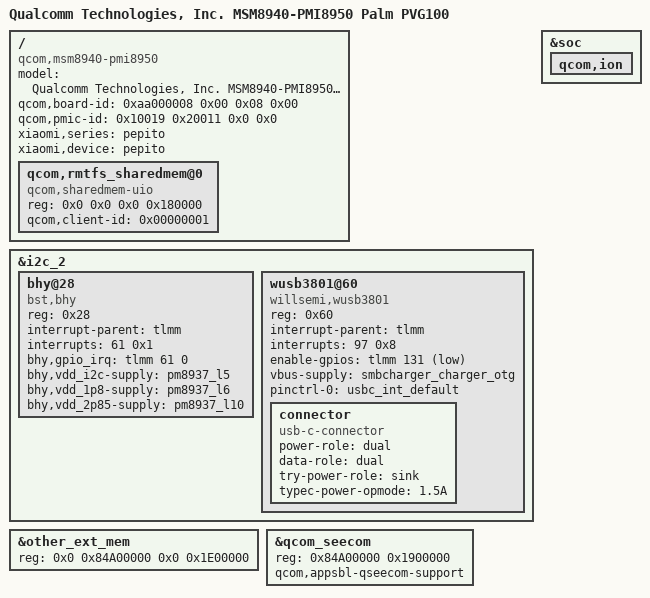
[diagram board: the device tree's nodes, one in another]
/*
 * Copyright (c) 2015-2016, 2018, The Linux Foundation. All rights reserved.
 *
 * This program is free software; you can redistribute it and/or modify
 * it under the terms of the GNU General Public License version 2 and
 * only version 2 as published by the Free Software Foundation.
 *
 * This program is distributed in the hope that it will be useful,
 * but WITHOUT ANY WARRANTY; without even the implied warranty of
 * MERCHANTABILITY or FITNESS FOR A PARTICULAR PURPOSE.  See the
 * GNU General Public License for more details.
 */

/dts-v1/;

#include "common/include/config.h"

#include "qcom/msm8940.dtsi"
/*
 * Pepito's companion PMIC is PMI8950 (per pmic-id = <0x10019 0x20011 ...>,
 * where 0x20011 identifies PMI8950).  The msm8940-pmi8950 fragment also
 * brings in the labibb regulators and wires lab/ibb supplies into
 * mdss_dsi0 — the regulator topology the FT8613 panel needs.
 *
 * The Mi8937 forward-port originally used msm8940-pmi8937.dtsi here
 * (a copy from a sibling that has no PMI), which left the kernel using
 * the wrong PMIC sub-device map and missing the panel supply wiring.
 */
#include "qcom/msm8940-pmi8950.dtsi"

#include "common/fragments/delete-msm89x7-camera-sensor-mtp.dtsi"
#include "common/fragments/qti-haptics.dtsi"
#include "common/fragments/restore-old-msm8937-camera-pinctrl.dtsi"

#include "common/common.dtsi"
#include "pepito/pepito.dtsi"

/ {
	model = "Qualcomm Technologies, Inc. MSM8940-PMI8950 Palm PVG100";
	compatible = "qcom,msm8940-pmi8950", "qcom,msm8940", "qcom,pmi8950", "xiaomi,pepito";
	qcom,board-id = <0xaa000008 0x00 0x08 0x00>;
	qcom,pmic-id = <0x10019 0x20011 0x0 0x0>;

#ifndef MI8937_V2
	xiaomi,series = "pepito";
	xiaomi,device = "pepito";
#endif
};

/*
 * SMMU re-enable (2026-06-03): the prior surgical-disable plan in
 * PLAN.md §3.1b was based on the theory that stock TZ couldn't tolerate
 * the qsmmu-v500 driver. Subsequent investigation (PLAN.md §3.1h) showed
 * that the kernel_src 4.9.227 kernel which "barely booted" on stock
 * Android 8 used the SAME arm-smmu.c driver and the SAME qcom,smmu-v2 +
 * qcom,qsmmu-v500 DTS bindings we have now. The SMMU was therefore not
 * the actual root cause of the silent reset at populate_rootfs — the
 * cause is somewhere else (SCM layer / DMA / init ordering — under
 * investigation). The apps_iommu / kgsl_smmu / msm_vidc / cam_smmu
 * disables are dropped here. Their inherited 4.9-tree configuration in
 * vendor-legacy/qcom/msm-arm-smmu-8937.dtsi is essentially identical to
 * what worked on 4.9, so no DTS additions are needed — only undoing the
 * status="disabled" overrides.
 *
 * i2c_2 stays disabled below — that issue is unrelated to SMMU.
 */

/*
 * BLSP1 QUP2 (i2c_2 @ 0x78b6000) is enabled by vendor-legacy/qcom/
 * msm8937-audio.dtsi for the WSA881x speaker codecs.  Lineage's
 * common/audio.dtsi then /delete-node/s those codec children.
 *
 * The real stock 3.18 DTB has TWO live children on i2c@78b6000:
 *   - bhy@28  compatible="bst,bhy" -> Bosch BHy hub = BMI160 accel+gyro
 *             (pepito's accelerometer; HAL = sensors.native.so).  IRQ
 *             GPIO 61; supplies vdd_i2c / vdd_1p8 / vdd_2p85.
 *   - wusb3801x@60 -> discrete USB-C CC/orientation controller.
 *
 * Re-enabled with children present (confirmed working on android8-adb:
 * 22 h/w sensors including accel/gyro/mag/pressure; [bhy_wq] kernel
 * thread live).  The zero-child i2c-msm-v2 probe hang is avoided by
 * having the bhy@28 child.
 *
 * wusb3801@60 (2026-07-16): pepito's stock HW has a Willsemi Type-C
 * CC/orientation controller here, left unmanaged for the whole bring-up.
 *
 * This node was originally added on the theory that leaving it unmanaged
 * caused a ~143s system-wide ANR (I2C contention during Android Auto USB
 * negotiation starving the sensors HAL's binder pool via bhy). That theory
 * was FALSIFIED the same day it was flashed: in a full reproduction every
 * i2c timeout was at bhy's 0x28 and none at 0x60, and this chip's reads
 * succeeded throughout the storm -- the bus was never wedged, the bhy hub
 * was (see PLAN-sensors.md). Android Auto also cannot work on this build
 * regardless: persist.vendor.usb.config is pinned adb-only, so the gadget
 * never enters accessory mode. Managing the port is still correct on its
 * own merits -- it is simply not the ANR fix.
 *
 * No QCOM downstream driver source for "qcom,wusb3801x" (the stock
 * compatible) was findable anywhere -- same GPL gap bhy hit -- so this
 * ports the mainline willsemi,wusb3801 driver instead
 * (drivers/usb/typec/wusb3801.c has the full API-compatibility/porting
 * notes). Property values below are decoded from the real stock DTB's
 * wusb3801,init-mode=0x24 (-> DRP + try-sink), host-current=0x01 (->
 * 1.5A), matched bit-for-bit against the ported driver's CTRL0 register
 * layout.
 *
 * Interrupt and enable-GPIO flags are decoded from stock rather than
 * guessed (an earlier revision copied bhy@28's edge-rising/active-high
 * style and got both wrong):
 *  - stock "interrupts = <0x61 0x2008>": 0x61 = 97, and 0x2008 is an
 *    IRQF_* encoding (IRQF_ONESHOT | IRQF_TRIGGER_LOW), of which only
 *    0x8 survives the irq domain's IRQ_TYPE_SENSE_MASK -> LEVEL_LOW.
 *    Level (not edge) also matters here because the chip holds INT
 *    asserted until REG_INT is read, so a missed edge would wedge the
 *    IRQ permanently.
 *  - stock "wusb3801,enb-gpio = <0xa7 0x83 0x01>": 0xa7 = tlmm,
 *    0x83 = 131, and the 0x01 flag cell is OF_GPIO_ACTIVE_LOW -- so
 *    the enable is active-low, and driving it high (as active-high
 *    flags did) held the chip disabled and NACKed every access.
 * Both corroborated by usbc_int_default biasing gpio97+gpio131 pull-up.
 *
 * drp-toggle-time (0x28 in stock) has no equivalent in the ported
 * driver and is dropped; chip power-on default applies.
 */
&i2c_2 {
	status = "okay";

	bhy@28 {
		compatible = "bst,bhy";
		reg = <0x28>;
		interrupt-parent = <&tlmm>;
		interrupts = <61 0x1>;
		bhy,gpio_irq = <&tlmm 61 0>;
		bhy,vdd_i2c-supply = <&pm8937_l5>;
		bhy,vdd_1p8-supply = <&pm8937_l6>;
		bhy,vdd_2p85-supply = <&pm8937_l10>;
	};

	wusb3801@60 {
		compatible = "willsemi,wusb3801";
		reg = <0x60>;
		interrupt-parent = <&tlmm>;
		interrupts = <97 0x8>;		/* IRQ_TYPE_LEVEL_LOW */
		enable-gpios = <&tlmm 131 1>;	/* GPIO_ACTIVE_LOW */
		vbus-supply = <&smbcharger_charger_otg>;
		pinctrl-names = "default";
		pinctrl-0 = <&usbc_int_default>;

		connector {
			compatible = "usb-c-connector";
			power-role = "dual";
			data-role = "dual";
			try-power-role = "sink";
			typec-power-opmode = "1.5A";
		};
	};
};

/*
 * other_ext_mem: restore the 30 MiB Palm reservation at 0x84A00000.
 *
 * vendor-legacy/qcom/msm8937.dtsi defines other_ext_mem at
 * 0x85B00000 / 0x0D00000 (13 MiB) — the layout used by post-update
 * Xiaomi TZ blobs on land/santoni/rolex/etc.  Pepito's stock TZ is
 * the older Palm 8.1 image (same root cause family as the SMMU
 * binding drift documented in PLAN.md §3.1b) and still DDR-xPU
 * protects the full 30 MiB region from 0x84A00000 to 0x86800000.
 *
 * Without this override the kernel believes the 17 MiB at
 * 0x84A00000–0x85B00000 is free RAM.  Page-allocator hands out
 * pages from that band during the initramfs-unpack burst in
 * populate_rootfs; the first write into one of those pages trips
 * TZ's xPU, which asserts PS_HOLD at the PMIC.  Result: silent
 * reset bypassing the kernel, no oops/panic visible — exactly the
 * §3.1f signature.
 *
 * Direct evidence: 4.9 boot log shows 2981888K total RAM after
 * reservations, our 4.19 build shows 2999296K — a delta of
 * 17408K = exactly the (0x1E00000 − 0xD00000) gap.
 *
 * Every other Mi8937 variant in this tree already has the same
 * override: ulysse/common/soc.dtsi (ugg) and
 * wingtech/msm8937/common/soc.dtsi (santoni, prada).  Pepito was
 * missed during the forward-port from 4.9.
 */
&other_ext_mem {
	reg = <0x0 0x84A00000 0x0 0x1E00000>;
};

/*
 * Palm stock DT only exposes the normal QSEECOM heap.  Drop the inherited
 * TA heap and memory pool while matching this old TZ/keymaster path.
 */
/delete-node/ &qseecom_ta_mem;

&soc {
	qcom,ion {
		/delete-node/ qcom,ion-heap@19;
	};
};

/*
 * qseecom secapp-region: Palm stock DTB maps the QSEE app loader window at
 * 0x84A00000 / 25 MiB. The inherited Xiaomi node points at the tail of that
 * protected range (0x85B00000 / 8 MiB), which does not match Palm TZ.
 */
&qcom_seecom {
	/delete-property/ qcom,commonlib64-loaded-by-uefi;
	reg = <0x84A00000 0x1900000>;
	qcom,appsbl-qseecom-support;
};

/*
 * RMTFS shared memory — modem EFS transfer buffer.
 *
 * reg = <addr_hi addr_lo size_hi size_lo> (root is #address/#size-cells = <2>).
 * addr = 0x0 => msm_sharedmem allocates coherent DMA memory dynamically
 * (is_addr_dynamic path); size = 0x180000 (1.5 MiB). This creates /dev/uio0
 * ("rmtfs") that rmt_storage mmaps and serves to the modem.
 *
 * This node is KEPT — it produces the working buffer (/dev/uio0 @ 0xf7300000).
 *
 * Two consumers serve this buffer's address to the modem, covering both
 * buffer-discovery methods seen in the MPSS family:
 *   1. userspace rmt_storage via RMTFS svc 14 ALLOC_BUFF (the official-4.19 /
 *      Xiaomi-modem path; rmt_storage reads the address from uio sysfs);
 *   2. in-kernel RFSA svc 28 GET_BUFF_ADDR (sharedmem_qmi.c re-added from
 *      stock 3.18; msm_sharedmem probe registers this node via
 *      sharedmem_qmi_add_entry, keyed by qcom,client-id 1 = MPSS_RMTS_CLIENT_ID).
 *
 * History (PLAN-radio.md): the RFSA re-port was removed 2026-07-06 (radio8)
 * on the theory that announcing svc 28 steered the modem away from
 * ALLOC_BUFF; that was FALSIFIED the same day — the stock A11's healthy Palm
 * modem acquires this buffer via RFSA GET_BUFF_ADDR on every boot
 * (/d/rmt_storage/info Request count increments per modem boot), so RFSA was
 * re-added (radio9). Necessary but not sufficient: pepito's modem sends ZERO
 * buffer-provider traffic (no ALLOC_BUFF, no GET_BUFF_ADDR, kernel- or
 * userspace-hosted — radio10) and fatals modem-internally in its
 * Smem_get_buffer/method-selection path before any request hits the wire.
 */
/ {
	qcom,rmtfs_sharedmem@0 {
		compatible = "qcom,sharedmem-uio";
		reg = <0x0 0x0 0x0 0x180000>;
		reg-names = "rmtfs";
		qcom,client-id = <0x00000001>;
	};
};
